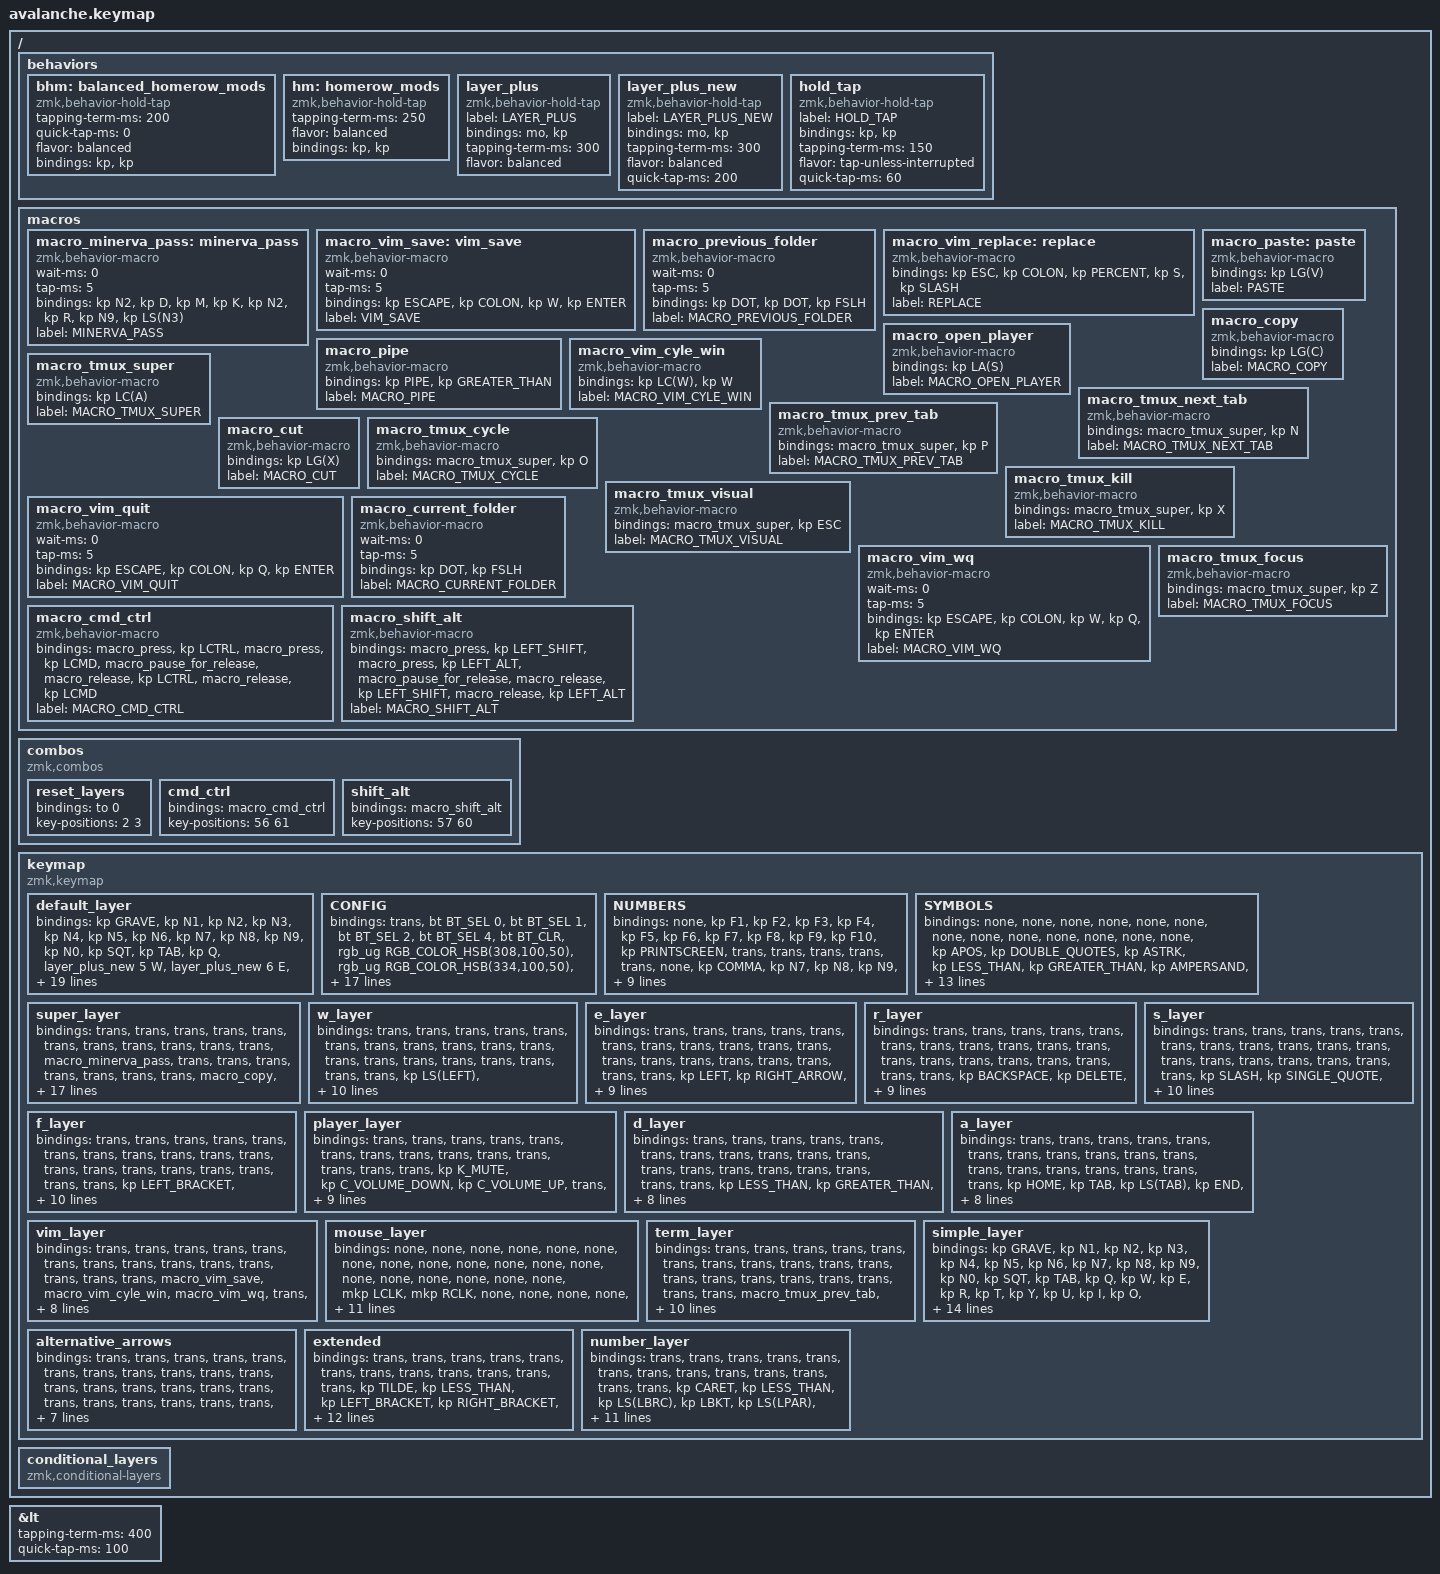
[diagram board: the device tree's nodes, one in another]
#define ZMK_POINTING_DEFAULT_MOVE_VAL 1200
#define ZMK_POINTING_DEFAULT_SCRL_VAL 20

#include <behaviors.dtsi>
#include <dt-bindings/zmk/bt.h>
#include <dt-bindings/zmk/keys.h>
#include <dt-bindings/zmk/pointing.h>
#include <dt-bindings/zmk/rgb.h>

&lt {
    tapping-term-ms = <400>;
    quick-tap-ms = <100>;
};

/ {
    behaviors {
        bhm: balanced_homerow_mods {
            compatible = "zmk,behavior-hold-tap";
            #binding-cells = <2>;
            tapping-term-ms = <200>;

            // <---[[moderate duration]]

            quick-tap-ms = <0>;
            flavor = "balanced";
            bindings = <&kp>, <&kp>;
        };

        hm: homerow_mods {
            compatible = "zmk,behavior-hold-tap";
            #binding-cells = <2>;
            tapping-term-ms = <250>;
            flavor = "balanced";
            bindings = <&kp>, <&kp>;
        };

        layer_plus: layer_plus {
            compatible = "zmk,behavior-hold-tap";
            label = "LAYER_PLUS";
            bindings = <&mo>, <&kp>;

            #binding-cells = <2>;
            tapping-term-ms = <300>;
            flavor = "balanced";
        };

        layer_plus_new: layer_plus_new {
            compatible = "zmk,behavior-hold-tap";
            label = "LAYER_PLUS_NEW";
            bindings = <&mo>, <&kp>;

            #binding-cells = <2>;
            tapping-term-ms = <300>;
            flavor = "balanced";
            quick-tap-ms = <200>;
        };

        hold_tap: hold_tap {
            compatible = "zmk,behavior-hold-tap";
            label = "HOLD_TAP";
            bindings = <&kp>, <&kp>;

            #binding-cells = <2>;
            tapping-term-ms = <150>;
            flavor = "tap-unless-interrupted";
            quick-tap-ms = <60>;
        };
    };

    macros {
        macro_minerva_pass: minerva_pass {
            compatible = "zmk,behavior-macro";
            #binding-cells = <0>;
            wait-ms = <0>;
            tap-ms = <5>;
            bindings = <&kp N2 &kp D &kp M &kp K &kp N2 &kp R &kp N9 &kp LS(N3)>;
            label = "MINERVA_PASS";
        };

        macro_vim_save: vim_save {
            compatible = "zmk,behavior-macro";
            #binding-cells = <0>;
            wait-ms = <0>;
            tap-ms = <5>;
            bindings = <&kp ESCAPE &kp COLON &kp W &kp ENTER>;
            label = "VIM_SAVE";
        };

        macro_previous_folder: macro_previous_folder {
            compatible = "zmk,behavior-macro";
            #binding-cells = <0>;
            wait-ms = <0>;
            tap-ms = <5>;
            bindings = <&kp DOT &kp DOT &kp FSLH>;
            label = "MACRO_PREVIOUS_FOLDER";
        };

        macro_vim_replace: replace {
            compatible = "zmk,behavior-macro";
            #binding-cells = <0>;
            bindings = <&kp ESC &kp COLON &kp PERCENT &kp S &kp SLASH>;
            label = "REPLACE";
        };

        macro_paste: paste {
            compatible = "zmk,behavior-macro";
            #binding-cells = <0>;
            bindings = <&kp LG(V)>;
            label = "PASTE";
        };

        macro_copy: macro_copy {
            compatible = "zmk,behavior-macro";
            #binding-cells = <0>;
            bindings = <&kp LG(C)>;
            label = "MACRO_COPY";
        };

        macro_open_player: macro_open_player {
            compatible = "zmk,behavior-macro";
            #binding-cells = <0>;
            bindings = <&kp LA(S)>;
            label = "MACRO_OPEN_PLAYER";
        };

        macro_pipe: macro_pipe {
            compatible = "zmk,behavior-macro";
            #binding-cells = <0>;
            bindings = <&kp PIPE &kp GREATER_THAN>;
            label = "MACRO_PIPE";
        };

        macro_vim_cyle_win: macro_vim_cyle_win {
            compatible = "zmk,behavior-macro";
            #binding-cells = <0>;
            bindings = <&kp LC(W) &kp W>;
            label = "MACRO_VIM_CYLE_WIN";
        };

        macro_tmux_super: macro_tmux_super {
            compatible = "zmk,behavior-macro";
            #binding-cells = <0>;
            bindings = <&kp LC(A)>;
            label = "MACRO_TMUX_SUPER";
        };

        macro_tmux_next_tab: macro_tmux_next_tab {
            compatible = "zmk,behavior-macro";
            #binding-cells = <0>;
            bindings = <&macro_tmux_super &kp N>;
            label = "MACRO_TMUX_NEXT_TAB";
        };

        macro_tmux_prev_tab: macro_tmux_prev_tab {
            compatible = "zmk,behavior-macro";
            #binding-cells = <0>;
            bindings = <&macro_tmux_super &kp P>;
            label = "MACRO_TMUX_PREV_TAB";
        };

        macro_cut: macro_cut {
            compatible = "zmk,behavior-macro";
            #binding-cells = <0>;
            bindings = <&kp LG(X)>;
            label = "MACRO_CUT";
        };

        macro_tmux_cycle: macro_tmux_cycle {
            compatible = "zmk,behavior-macro";
            #binding-cells = <0>;
            bindings = <&macro_tmux_super &kp O>;
            label = "MACRO_TMUX_CYCLE";
        };

        macro_tmux_kill: macro_tmux_kill {
            compatible = "zmk,behavior-macro";
            #binding-cells = <0>;
            bindings = <&macro_tmux_super &kp X>;
            label = "MACRO_TMUX_KILL";
        };

        macro_tmux_visual: macro_tmux_visual {
            compatible = "zmk,behavior-macro";
            #binding-cells = <0>;
            bindings = <&macro_tmux_super &kp ESC>;
            label = "MACRO_TMUX_VISUAL";
        };

        macro_vim_quit: macro_vim_quit {
            compatible = "zmk,behavior-macro";
            #binding-cells = <0>;
            wait-ms = <0>;
            tap-ms = <5>;
            bindings = <&kp ESCAPE &kp COLON &kp Q &kp ENTER>;
            label = "MACRO_VIM_QUIT";
        };

        macro_vim_wq: macro_vim_wq {
            compatible = "zmk,behavior-macro";
            #binding-cells = <0>;
            wait-ms = <0>;
            tap-ms = <5>;
            bindings = <&kp ESCAPE &kp COLON &kp W &kp Q &kp ENTER>;
            label = "MACRO_VIM_WQ";
        };

        macro_current_folder: macro_current_folder {
            compatible = "zmk,behavior-macro";
            #binding-cells = <0>;
            wait-ms = <0>;
            tap-ms = <5>;
            bindings = <&kp DOT &kp FSLH>;
            label = "MACRO_CURRENT_FOLDER";
        };

        macro_tmux_focus: macro_tmux_focus {
            compatible = "zmk,behavior-macro";
            #binding-cells = <0>;
            bindings = <&macro_tmux_super &kp Z>;
            label = "MACRO_TMUX_FOCUS";
        };

        macro_cmd_ctrl: macro_cmd_ctrl {
            compatible = "zmk,behavior-macro";
            #binding-cells = <0>;
            bindings =
                <&macro_press>,
                <&kp LCTRL>,
                <&macro_press>,
                <&kp LCMD>,
                <&macro_pause_for_release>,
                <&macro_release>,
                <&kp LCTRL>,
                <&macro_release>,
                <&kp LCMD>;

            label = "MACRO_CMD_CTRL";
        };

        macro_shift_alt: macro_shift_alt {
            compatible = "zmk,behavior-macro";
            #binding-cells = <0>;
            bindings =
                <&macro_press>,
                <&kp LEFT_SHIFT>,
                <&macro_press>,
                <&kp LEFT_ALT>,
                <&macro_pause_for_release>,
                <&macro_release>,
                <&kp LEFT_SHIFT>,
                <&macro_release>,
                <&kp LEFT_ALT>;

            label = "MACRO_SHIFT_ALT";
        };
    };

    combos {
        compatible = "zmk,combos";

        reset_layers {
            bindings = <&to 0>;
            key-positions = <2 3>;
        };

        cmd_ctrl {
            bindings = <&macro_cmd_ctrl>;
            key-positions = <56 61>;
        };

        shift_alt {
            bindings = <&macro_shift_alt>;
            key-positions = <57 60>;
        };
    };

    keymap {
        compatible = "zmk,keymap";

        default_layer {
            // ---------------------------------------------------------------------------------------------------------------------------------------------
            //            |  `  |  1  |  2  |  3  |  4  |  5  |                                             |  6  |  7  |  8  |  9  |  0  |  '  |
            //            | TAB |  Q  |  W  |  E  |  R  |  T  |                                             |  Y  |  U  |  I  |  O  |  P  |  [  | 
            //    |  ESC  |CTRL |  A  |  S  |  D  |  F  |  G  |                                             |  H  |  J  |  K  |  L  |  ;  |  '  |  \   |
            //            |SHIFT|  Z  |  X  |  C  |  V  |  B  |  DEL  |                              | BSPC |  N  |  M  |  ,  |  .  |  /  |  -  |
            //                        | GUI | ALT |SPACE|RAISE| ENTER |                              | ENTER|  =  |SPACE|MO(1)|MO(2)|
            // ---------------------------------------------------------------------------------------------------------------------------------------------

            bindings = <
&kp GRAVE         &kp N1          &kp N2                &kp N3               &kp N4                   &kp N5                                            &kp N6                  &kp N7         &kp N8                   &kp N9  &kp N0                &kp SQT
&kp TAB           &kp Q           &layer_plus_new 5 W   &layer_plus_new 6 E  &layer_plus_new 7 R      &kp T                                             &kp Y                   &kp U          &kp I                    &kp O   &layer_plus_new 10 P  &kp MINUS
&kp LEFT_BRACKET  &kp ESC         &layer_plus_new 12 A  &layer_plus_new 8 S  &layer_plus_new 11 D     &layer_plus_new 9 F    &layer_plus 14 G                                   &kp H          &kp J                    &kp K   &kp L                 &bhm LEFT_SHIFT SEMICOLON  &hm RIGHT_ALT EQUAL      &kp RIGHT_BRACKET
&kp LEFT_GUI      &kp Z           &kp X                 &kp C                &kp V                    &kp B                  &kp DELETE        &tog 16  &mo 1                   &kp BACKSPACE  &kp N                    &kp M   &kp COMMA             &kp PERIOD                 &hm RIGHT_COMMAND SLASH  &mo 2
                  &kp C_PREVIOUS  &mo 4                 &bhm LCTRL SPACE     &bhm LEFT_ALT BACKSPACE  &bhm LEFT_SHIFT ENTER                             &bhm RIGHT_SHIFT ENTER  &kp LEFT_ALT   &bhm LEFT_CONTROL SPACE  &mo 19  &kp C_NEXT
            >;

            sensor-bindings =
                <&inc_dec_kp C_VOL_DN C_VOL_UP>,
                <&inc_dec_kp C_AC_SCROLL_UP C_AC_SCROLL_DOWN>;
        };

        CONFIG {
            bindings = <
&trans  &bt BT_SEL 0  &bt BT_SEL 1    &bt BT_SEL 2    &bt BT_SEL 4    &bt BT_CLR                       &rgb_ug RGB_COLOR_HSB(308,100,50)  &rgb_ug RGB_COLOR_HSB(334,100,50)  &rgb_ug RGB_COLOR_HSB(121,100,48)  &trans           &rgb_ug RGB_HUD  &rgb_ug RGB_HUI
&trans  &bt BT_PRV    &bt BT_NXT      &kp END         &bt BT_CLR_ALL  &trans                           &rgb_ug RGB_COLOR_HSB(0,100,50)    &rgb_ug RGB_COLOR_HSB(182,100,50)  &rgb_ug RGB_COLOR_HSB(251,100,49)  &trans           &rgb_ug RGB_SAD  &rgb_ug RGB_SAI
&trans  &trans        &kp LEFT_ARROW  &kp DOWN_ARROW  &kp RIGHT       &trans           &trans                                             &trans                             &trans                             &trans           &trans           &rgb_ug RGB_BRD  &rgb_ug RGB_BRI  &bt BT_CLR
&trans  &trans        &trans          &trans          &trans          &trans           &trans  &trans  &trans                             &trans                             &rgb_ug RGB_EFR                    &rgb_ug RGB_EFF  &trans           &trans           &rgb_ug RGB_SPD  &rgb_ug RGB_SPI
        &trans        &trans          &trans          &trans          &macro_vim_save                  &trans                             &trans                             &trans                             &trans           &trans
            >;

            sensor-bindings = <&inc_dec_kp C_NEXT C_PREVIOUS>;
        };

        NUMBERS {
            // ---------------------------------------------------------------------------------------------------------------------------------------------
            //            |     |     |     |     |     |     |                                          |     |     |     |     |     |     |
            //            |     | HOME|  UP | END |     |     |                                          |     |HOME |     |END  |     |     |
            //       |    |     | LEFT| DOWN|RIGHT|     |     |                                          |SCLUP|LEFT |  UP |  A  |PG_UP|     |    |
            //            |     |     |     |     |     |     |     |                              |     |SCLDN|LEFT | DOWN|RIGHT|PG_DN|     |
            //                        |     |     |     |     |     |                              |     |     |     |     |     |
            // ---------------------------------------------------------------------------------------------------------------------------------------------

            bindings = <
&none   &kp F1  &kp F2  &kp F3  &kp F4  &kp F5                 &kp F6     &kp F7      &kp F8        &kp F9        &kp F10       &kp PRINTSCREEN
&trans  &trans  &trans  &trans  &trans  &none                  &kp COMMA  &kp N7      &kp N8        &kp N9        &kp PLUS      &none
&trans  &trans  &trans  &trans  &trans  &none   &none                     &kp PERIOD  &kp NUMBER_4  &kp N5        &kp NUMBER_6  &kp BACKSPACE    &none      &none
&trans  &none   &none   &none   &none   &trans  &trans  &none  &none      &trans      &kp NUMBER_0  &kp NUMBER_1  &kp NUMBER_2  &kp NUMBER_3     &kp EQUAL  &none
        &trans  &trans  &trans  &trans  &trans                 &trans     &trans      &trans        &trans        &trans
            >;

            sensor-bindings = <&inc_dec_kp PAGE_UP PAGE_DOWN>;
        };

        SYMBOLS {
            bindings = <
&none            &none           &none              &none       &none          &none                              &none          &none      &none             &none                 &none                  &none
&none            &kp APOS        &kp DOUBLE_QUOTES  &kp ASTRK   &kp LESS_THAN  &kp GREATER_THAN                   &kp AMPERSAND  &kp TILDE  &kp LEFT_BRACKET  &kp RIGHT_BRACKET     &kp PERCENT            &none
&macro_vim_save  &kp UNDERSCORE  &kp EXCLAMATION    &kp MINUS   &kp PLUS       &kp EQUAL         &kp HASH                        &kp PIPE   &kp COLON         &kp LEFT_PARENTHESIS  &kp RIGHT_PARENTHESIS  &kp QUESTION     &none        &none
&none            &kp CARET       &kp COMMA          &kp PERIOD  &kp BACKSLASH  &kp GRAVE         &none     &none  &none          &none      &kp SLASH         &kp DOLLAR            &kp LEFT_BRACE         &kp RIGHT_BRACE  &kp AT_SIGN  &none
                 &none           &none              &none       &none          &none                              &none          &none      &none             &none                 &none
            >;

            sensor-bindings = <&inc_dec_kp RIGHT LEFT>;
        };

        super_layer {
            bindings = <
&trans  &trans                        &trans                        &trans                        &trans                        &trans                                                        &trans  &trans       &trans        &trans         &trans         &macro_minerva_pass
&trans  &trans                        &trans                        &trans                        &trans                        &trans                                                        &trans  &macro_copy  &macro_paste  &macro_cut     &trans         &trans
&trans  &kp LS(LA(LC(LG(NUMBER_6))))  &kp LS(LA(LC(LG(NUMBER_1))))  &kp LS(LA(LC(LG(NUMBER_2))))  &kp LS(LA(LC(LG(NUMBER_3))))  &kp LS(LA(LC(LG(NUMBER_4))))  &kp LS(LA(LC(LG(N5))))                  &kp LC(A)    &kp LG(A)     &kp LG(Z)      &trans         &trans               &trans  &kp LA(LC(DELETE))
&trans  &trans                        &trans                        &trans                        &trans                        &trans                        &trans                  &trans  &trans  &trans       &kp LC(C)     &kp LG(SPACE)  &kp LA(LC(X))  &kp LG(X)            &trans  &trans
        &trans                        &trans                        &trans                        &trans                        &trans                                                        &trans  &trans       &trans        &trans         &trans
            >;

            sensor-bindings =
                <&inc_dec_kp K_SCROLL_DOWN K_SCROLL_UP>,
                <&inc_dec_kp K_SCROLL_DOWN K_SCROLL_UP>;
        };

        w_layer {
            bindings = <
&trans  &trans  &trans  &trans  &trans  &trans                  &trans  &trans            &trans                  &trans             &trans                   &trans
&trans  &trans  &trans  &trans  &trans  &trans                  &trans  &kp LS(LEFT)      &kp LS(RIGHT_ARROW)     &trans             &trans                   &trans
&trans  &trans  &trans  &trans  &trans  &trans  &trans                  &kp LG(LS(LEFT))  &kp LS(LA(LEFT_ARROW))  &kp LS(LA(RIGHT))  &kp LS(LG(RIGHT_ARROW))  &trans  &trans  &trans
&trans  &trans  &trans  &trans  &trans  &trans  &trans  &trans  &trans  &trans            &trans                  &trans             &trans                   &trans  &trans  &trans
        &trans  &trans  &trans  &trans  &trans                  &trans  &trans            &trans                  &trans             &trans
            >;
        };

        e_layer {
            bindings = <
&trans  &trans  &trans  &trans  &trans  &trans                  &trans  &trans        &trans              &trans         &trans               &trans
&trans  &trans  &trans  &trans  &trans  &trans                  &trans  &kp LEFT      &kp RIGHT_ARROW     &trans         &trans               &trans
&trans  &trans  &trans  &trans  &trans  &trans  &trans                  &kp LG(LEFT)  &kp LA(LEFT_ARROW)  &kp LA(RIGHT)  &kp LG(RIGHT_ARROW)  &trans  &trans  &trans
&trans  &trans  &trans  &trans  &trans  &trans  &trans  &trans  &trans  &trans        &trans              &kp ENTER      &kp ENTER            &trans  &trans  &trans
        &trans  &trans  &trans  &trans  &trans                  &trans  &trans        &trans              &trans         &trans
            >;
        };

        r_layer {
            bindings = <
&trans  &trans  &trans  &trans  &trans  &trans                  &trans  &trans             &trans             &trans          &trans          &trans
&trans  &trans  &trans  &trans  &trans  &trans                  &trans  &kp BACKSPACE      &kp DELETE         &trans          &trans          &trans
&trans  &trans  &trans  &trans  &trans  &trans  &trans                  &kp LG(BACKSPACE)  &kp LA(BACKSPACE)  &kp LA(DELETE)  &kp LG(DELETE)  &trans  &trans  &trans
&trans  &trans  &trans  &trans  &trans  &trans  &trans  &trans  &trans  &trans             &trans             &trans          &trans          &trans  &trans  &trans
        &trans  &trans  &trans  &trans  &trans                  &trans  &trans             &trans             &trans          &trans
            >;
        };

        s_layer {
            bindings = <
&trans  &trans  &trans  &trans  &trans  &trans                  &trans     &trans            &trans             &trans         &trans         &trans
&trans  &trans  &trans  &trans  &trans  &trans                  &kp SLASH  &kp SINGLE_QUOTE  &kp DOUBLE_QUOTES  &kp GRAVE      &kp BACKSLASH  &trans
&trans  &trans  &trans  &trans  &trans  &trans  &trans                     &kp PIPE          &kp COMMA          &kp PERIOD     &kp COLON      &kp QUESTION  &trans       &trans
&trans  &trans  &trans  &trans  &trans  &trans  &trans  &trans  &trans     &trans            &macro_pipe        &kp SEMICOLON  &kp AMPERSAND  &kp TILDE     &kp AT_SIGN  &trans
        &trans  &trans  &trans  &trans  &trans                  &trans     &trans            &trans             &trans         &trans
            >;
        };

        f_layer {
            bindings = <
&trans  &trans  &trans  &trans  &trans  &trans                  &trans  &trans            &trans                &trans                 &trans           &trans
&trans  &trans  &trans  &trans  &trans  &trans                  &trans  &kp LEFT_BRACKET  &kp RIGHT_BRACKET     &kp EXCLAMATION        &trans           &trans
&trans  &trans  &trans  &trans  &trans  &trans  &trans                  &kp CARET         &kp LEFT_PARENTHESIS  &kp RIGHT_PARENTHESIS  &kp QUESTION     &kp DOLLAR  &trans  &trans
&trans  &trans  &trans  &trans  &trans  &trans  &trans  &trans  &trans  &trans            &kp UNDERSCORE        &kp LEFT_BRACE         &kp RIGHT_BRACE  &kp MINUS   &trans  &trans
        &trans  &trans  &trans  &trans  &trans                  &trans  &trans            &trans                &trans                 &trans
            >;
        };

        player_layer {
            bindings = <
&trans  &trans  &trans      &trans             &trans           &trans                      &trans  &trans  &trans  &trans  &trans  &trans
&trans  &trans  &kp K_MUTE  &kp C_VOLUME_DOWN  &kp C_VOLUME_UP  &trans                      &trans  &trans  &trans  &trans  &trans  &trans
&trans  &trans  &trans      &kp C_PLAY_PAUSE   &kp C_PREV       &kp C_NEXT  &trans                  &trans  &trans  &trans  &trans  &trans  &trans  &trans
&trans  &trans  &trans      &trans             &trans           &trans      &trans  &trans  &trans  &trans  &trans  &trans  &trans  &trans  &trans  &trans
        &trans  &trans      &trans             &trans           &trans                      &trans  &trans  &trans  &trans  &trans
            >;
        };

        d_layer {
            bindings = <
&trans  &trans  &trans  &trans  &trans  &trans                  &trans  &trans         &trans            &trans        &trans     &trans
&trans  &trans  &trans  &trans  &trans  &trans                  &trans  &kp LESS_THAN  &kp GREATER_THAN  &kp HASH      &trans     &trans
&trans  &trans  &trans  &trans  &trans  &trans  &trans                  &trans         &kp PLUS          &kp MINUS     &kp EQUAL  &trans       &trans  &trans
&trans  &trans  &trans  &trans  &trans  &trans  &trans  &trans  &trans  &trans         &trans            &kp ASTERISK  &kp SLASH  &kp PERCENT  &trans  &trans
        &trans  &trans  &trans  &trans  &trans                  &trans  &trans         &trans            &trans        &trans
            >;
        };

        a_layer {
            bindings = <
&trans  &trans  &trans  &trans  &trans  &trans                  &trans    &trans    &trans          &trans        &trans         &trans
&trans  &trans  &trans  &trans  &trans  &trans                  &kp HOME  &kp TAB   &kp LS(TAB)     &kp END       &trans         &trans
&trans  &trans  &trans  &trans  &trans  &trans  &trans                    &kp LEFT  &kp DOWN_ARROW  &kp UP_ARROW  &kp RIGHT      &kp BACKSPACE  &trans  &trans
&trans  &trans  &trans  &trans  &trans  &trans  &trans  &trans  &trans    &trans    &trans          &kp ENTER     &kp LS(ENTER)  &trans         &trans  &trans
        &trans  &trans  &trans  &trans  &trans                  &trans    &trans    &trans          &trans        &trans
            >;
        };

        vim_layer {
            bindings = <
&trans  &trans  &trans           &trans               &trans         &trans                  &trans  &trans  &trans  &trans  &trans  &trans
&trans  &trans  &macro_vim_save  &macro_vim_cyle_win  &macro_vim_wq  &trans                  &trans  &trans  &trans  &trans  &trans  &trans
&trans  &trans  &trans           &kp COLON            &kp SLASH      &trans  &trans                  &trans  &trans  &trans  &trans  &trans  &trans  &trans
&trans  &trans  &trans           &trans               &trans         &trans  &trans  &trans  &trans  &trans  &trans  &trans  &trans  &trans  &trans  &trans
        &trans  &trans           &trans               &trans         &trans                  &trans  &trans  &trans  &trans  &trans
            >;
        };

        mouse_layer {
            bindings = <
&none  &none  &none      &none      &none  &none                &none  &none           &none           &none         &none            &none
&none  &none  &none      &none      &none  &none                &none  &mkp LCLK       &mkp RCLK       &none         &none            &none
&none  &none  &mkp LCLK  &mkp RCLK  &none  &none  &none                &mmv MOVE_LEFT  &mmv MOVE_DOWN  &mmv MOVE_UP  &mmv MOVE_RIGHT  &none  &none  &none
&none  &none  &none      &none      &none  &none  &none  &none  &none  &none           &none           &msc SCRL_UP  &msc SCRL_DOWN   &none  &none  &none
       &none  &none      &none      &none  &none                &none  &none           &none           &none         &none
            >;

            sensor-bindings =
                <&inc_dec_kp UP_ARROW DOWN_ARROW>,
                <&inc_dec_kp A B>;
        };

        term_layer {
            bindings = <
&trans  &trans  &trans  &trans  &trans  &trans                  &trans  &trans                &trans                &trans                  &trans             &trans
&trans  &trans  &trans  &trans  &trans  &trans                  &trans  &macro_tmux_prev_tab  &macro_tmux_next_tab  &macro_tmux_cycle       &trans             &trans
&trans  &trans  &trans  &trans  &trans  &trans  &trans                  &trans                &macro_tmux_visual    &macro_tmux_kill        &macro_tmux_focus  &trans  &trans  &trans
&trans  &trans  &trans  &trans  &trans  &trans  &trans  &trans  &trans  &trans                &trans                &macro_previous_folder  &trans             &trans  &trans  &trans
        &trans  &trans  &trans  &trans  &trans                  &trans  &trans                &trans                &trans                  &trans
            >;
        };

        simple_layer {
            bindings = <
&kp GRAVE     &kp N1                &kp N2  &kp N3     &kp N4          &kp N5                               &kp N6        &kp N7        &kp N8     &kp N9  &kp N0            &kp SQT
&kp TAB       &kp Q                 &kp W   &kp E      &kp R           &kp T                                &kp Y         &kp U         &kp I      &kp O   &layer_plus 10 P  &kp MINUS
&kp LEFT_ALT  &hm LEFT_CONTROL ESC  &kp A   &kp S      &kp D           &kp F                &kp G                         &kp H         &kp J      &kp K   &kp L             &bhm LEFT_SHIFT SEMICOLON  &hm RIGHT_CONTROL EQUAL  &kp LEFT_GUI
&kp LEFT_GUI  &kp Z                 &kp X   &kp C      &kp V           &kp B                &trans  &trans  &kp NUMBER_1  &kp NUMBER_2  &kp N      &kp M   &kp COMMA         &kp PERIOD                 &bhm RIGHT_ALT SLASH     &mo 2
              &kp C_PREVIOUS        &mo 4   &kp SPACE  &kp LEFT_SHIFT  &layer_plus 2 ENTER                  &kp NUMBER_3  &kp NUMBER_4  &kp SPACE  &mo 13  &kp C_NEXT
            >;

            sensor-bindings =
                <&inc_dec_kp C_VOL_DN C_VOL_UP>,
                <&inc_dec_kp C_AC_SCROLL_UP C_AC_SCROLL_DOWN>;
        };

        alternative_arrows {
            bindings = <
&trans  &trans  &trans  &trans    &trans     &trans                  &trans  &trans    &trans  &trans  &trans  &trans
&trans  &trans  &trans  &trans    &trans     &trans                  &trans  &trans    &trans  &trans  &trans  &trans
&trans  &trans  &trans  &trans    &trans     &trans  &trans                  &trans    &trans  &trans  &trans  &trans  &trans  &trans
&trans  &trans  &trans  &trans    &trans     &trans  &trans  &trans  &trans  &trans    &trans  &trans  &trans  &trans  &trans  &trans
        &trans  &trans  &kp LEFT  &kp RIGHT  &trans                  &trans  &kp DOWN  &kp UP  &trans  &trans
            >;
        };

        extended {
            bindings = <
&trans     &trans         &trans            &trans                &trans                 &trans                            &trans  &trans    &trans       &trans     &trans         &trans
&kp TILDE  &kp LESS_THAN  &kp LEFT_BRACKET  &kp RIGHT_BRACKET     &kp GREATER_THAN       &trans                            &trans  &kp TAB   &kp LS(TAB)  &trans     &trans         &trans
&trans     &kp PIPE       &kp UNDERSCORE    &kp LEFT_PARENTHESIS  &kp RIGHT_PARENTHESIS  &kp MINUS  &kp AMPERSAND                  &kp LEFT  &kp DOWN     &kp UP     &kp RIGHT      &kp BACKSPACE  &trans  &trans
&kp SLASH  &kp AT         &kp LEFT_BRACE    &kp RIGHT_BRACE       &kp COLON              &trans     &trans         &trans  &trans  &trans    &trans       &kp ENTER  &kp LS(ENTER)  &trans         &trans  &trans
           &trans         &trans            &trans                &trans                 &trans                            &trans  &trans    &trans       &trans     &trans
            >;
        };

        number_layer {
            bindings = <
&trans  &trans        &trans         &trans         &trans        &trans                         &trans        &trans    &trans        &trans            &trans         &trans
&trans  &kp CARET     &kp LESS_THAN  &kp LS(LBRC)   &kp LBKT      &kp LS(LPAR)                   &kp LS(RPAR)  &kp RBKT  &kp LS(RBRC)  &kp GREATER_THAN  &kp DOLLAR     &trans
&trans  &kp SQT       &kp N1         &kp N2         &kp N3        &kp N4         &kp N5                        &kp N6    &kp N7        &kp N8            &kp N9         &kp N0     &kp LS(DQT)  &trans
&trans  &kp LS(EXCL)  &kp LS(AT)     &kp LS(POUND)  &kp LS(DLLR)  &kp LS(PRCNT)  &trans  &trans  &trans        &trans    &kp COMMA     &kp DOT           &kp LS(COLON)  &kp GRAVE  &kp LS(DQT)  &trans
        &trans        &trans         &trans         &trans        &trans                         &trans        &trans    &trans        &trans            &trans
            >;
        };
    };

    conditional_layers { compatible = "zmk,conditional-layers"; };
};
